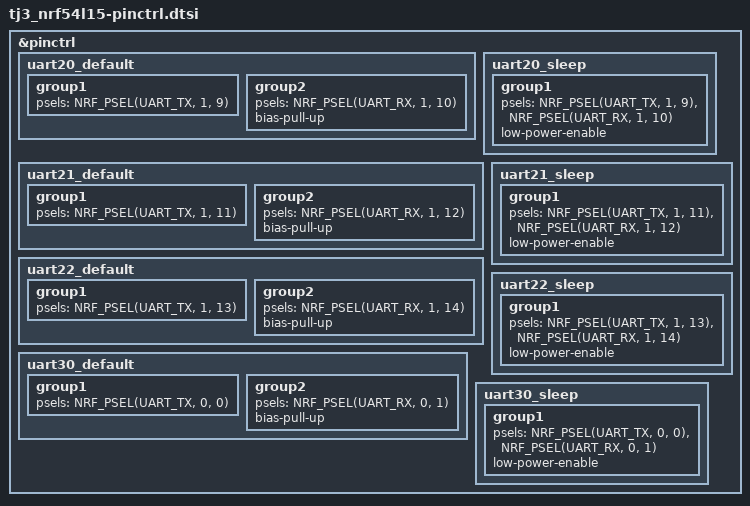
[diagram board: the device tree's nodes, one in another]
/*
 * Copyright (c) 2024 Nordic Semiconductor ASA
 * SPDX-License-Identifier: Apache-2.0
 */

&pinctrl {

	/omit-if-no-ref/ uart20_default: uart20_default {
		group1 {
			psels = <NRF_PSEL(UART_TX, 1, 9)>;
		};

		group2 {
			psels = <NRF_PSEL(UART_RX, 1, 10)>;
			bias-pull-up;
		};
	};

	/omit-if-no-ref/ uart20_sleep: uart20_sleep {
		group1 {
			psels = <NRF_PSEL(UART_TX, 1, 9)>,
					<NRF_PSEL(UART_RX, 1, 10)>;
			low-power-enable;
		};
	};

	/omit-if-no-ref/ uart21_default: uart21_default {
		group1 {
			psels = <NRF_PSEL(UART_TX, 1, 11)>;
		};

		group2 {
			psels = <NRF_PSEL(UART_RX, 1, 12)>;
			bias-pull-up;
		};
	};

	/omit-if-no-ref/ uart21_sleep: uart21_sleep {
		group1 {
			psels = <NRF_PSEL(UART_TX, 1, 11)>,
					<NRF_PSEL(UART_RX, 1, 12)>;
			low-power-enable;
		};
	};


	/omit-if-no-ref/ uart22_default: uart22_default {
		group1 {
			psels = <NRF_PSEL(UART_TX, 1, 13)>;
		};

		group2 {
			psels = <NRF_PSEL(UART_RX, 1, 14)>;
			bias-pull-up;
		};
	};

	/omit-if-no-ref/ uart22_sleep: uart22_sleep {
		group1 {
			psels = <NRF_PSEL(UART_TX, 1, 13)>,
					<NRF_PSEL(UART_RX, 1, 14)>;
			low-power-enable;
		};
	};

	/omit-if-no-ref/ uart30_default: uart30_default {
		group1 {
			psels = <NRF_PSEL(UART_TX, 0, 0)>;
		};

		group2 {
			psels = <NRF_PSEL(UART_RX, 0, 1)>;
			bias-pull-up;
		};
	};

	/omit-if-no-ref/ uart30_sleep: uart30_sleep {
		group1 {
			psels = <NRF_PSEL(UART_TX, 0, 0)>,
					<NRF_PSEL(UART_RX, 0, 1)>;
			low-power-enable;
		};
	};
};
